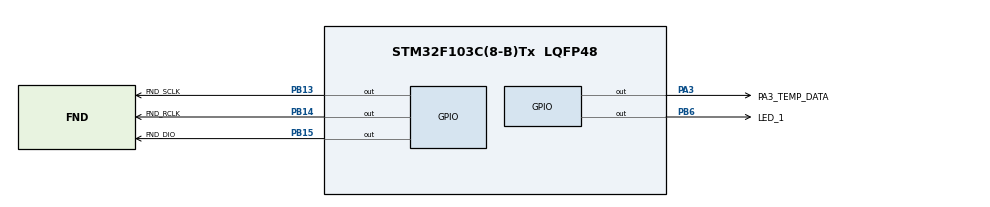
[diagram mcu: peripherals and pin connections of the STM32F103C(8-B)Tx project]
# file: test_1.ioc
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Mcu.Family=STM32F1
Mcu.Name=STM32F103C(8-B)Tx
Mcu.Package=LQFP48
NVIC.PriorityGroup=NVIC_PRIORITYGROUP_4
NVIC.TIM2_IRQn=true\:0\:0\:false\:false\:true\:true\:true\:true
PA3.GPIO_Label=PA3_TEMP_DATA
PA3.GPIO_ModeDefaultOutputPP=GPIO_MODE_OUTPUT_PP
PA3.GPIO_PuPd=GPIO_PULLUP
PA3.GPIO_Speed=GPIO_SPEED_FREQ_HIGH
PA3.PinState=GPIO_PIN_SET
PA3.Signal=GPIO_Output
PB13.GPIO_Label=FND_SCLK
PB13.GPIO_PuPd=GPIO_PULLUP
PB13.GPIO_Speed=GPIO_SPEED_FREQ_HIGH
PB13.PinState=GPIO_PIN_SET
PB13.Signal=GPIO_Output
PB14.GPIO_Label=FND_RCLK
PB14.GPIO_PuPd=GPIO_PULLUP
PB14.PinState=GPIO_PIN_SET
PB14.Signal=GPIO_Output
PB15.GPIO_Label=FND_DIO
PB15.GPIO_PuPd=GPIO_PULLDOWN
PB15.GPIO_Speed=GPIO_SPEED_FREQ_HIGH
PB15.PinState=GPIO_PIN_SET
PB15.Signal=GPIO_Output
PB6.GPIO_Label=LED_1
PB6.GPIO_ModeDefaultOutputPP=GPIO_MODE_OUTPUT_PP
PB6.GPIO_PuPd=GPIO_PULLUP
PB6.GPIO_Speed=GPIO_SPEED_FREQ_LOW
PB6.PinState=GPIO_PIN_SET
PB6.Signal=GPIO_Output
ProjectManager.HeapSize=0x200
ProjectManager.StackSize=0x400
ProjectManager.TargetToolchain=STM32CubeIDE
RCC.APB1Freq_Value=8000000
RCC.APB2Freq_Value=8000000
TIM2.Prescaler=(10000-1)
VP_SYS_VS_ND.Mode=No_Debug
VP_TIM2_VS_ClockSourceINT.Mode=Internal
board=custom

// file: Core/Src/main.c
/* USER CODE BEGIN Header */
/**
  ******************************************************************************
  * @file           : main.c
  * @brief          : Main program body
  ******************************************************************************
  * @attention
  *
  * Copyright (c) 2025 STMicroelectronics.
  * All rights reserved.
  *
  * This software is licensed under terms that can be found in the LICENSE file
  * in the root directory of this software component.
  * If no LICENSE file comes with this software, it is provided AS-IS.
  *
  ******************************************************************************
  */
/* USER CODE END Header */
#include "main.h"

/* USER CODE BEGIN Includes */
#include "fnd_controller.h"
/* USER CODE END Includes */

TIM_HandleTypeDef htim2;

void SystemClock_Config(void);
static void MX_GPIO_Init(void);
static void MX_TIM2_Init(void);

int main(void)
{

  /* USER CODE BEGIN 1 */
	Set_Up();

  /* USER CODE END 1 */

  /* MCU Configuration--------------------------------------------------------*/

  /* Reset of all peripherals, Initializes the Flash interface and the Systick. */
  HAL_Init();

  /* Configure the system clock */
  SystemClock_Config();

  /* Initialize all configured peripherals */
  MX_GPIO_Init();
  MX_TIM2_Init();
  /* USER CODE BEGIN 2 */
  HAL_TIM_Base_Start_IT(&htim2);
  /* USER CODE END 2 */

  /* Infinite loop */
  /* USER CODE BEGIN WHILE */
  while (1)
  {
	/* each segment's number
	  unsigned char a = 0b0001;
	for(int i = 0; i <= 8;i++)
	{
		send(~a);
		send(0b0001);
		HAL_GPIO_WritePin(FND_RCLK_GPIO_Port, FND_RCLK_Pin, 0);
		HAL_GPIO_WritePin(FND_RCLK_GPIO_Port, FND_RCLK_Pin, 1);
		a = a << 1;
		HAL_Delay(2000);
	}
	*/

	for (int i = 10; i <= 9999; i++) {
		digit_temper_replay(i, 50); //send counter 0-9999 with delay 50 cicles and hide zero
	}

    /* USER CODE END WHILE */

  }
}

void SystemClock_Config(void)
{
  RCC_OscInitTypeDef RCC_OscInitStruct = {0};
  RCC_ClkInitTypeDef RCC_ClkInitStruct = {0};

  /** Initializes the RCC Oscillators according to the specified parameters
  * in the RCC_OscInitTypeDef structure.
  */
  RCC_OscInitStruct.OscillatorType = RCC_OSCILLATORTYPE_HSI;
  RCC_OscInitStruct.HSIState = RCC_HSI_ON;
  RCC_OscInitStruct.HSICalibrationValue = RCC_HSICALIBRATION_DEFAULT;
  RCC_OscInitStruct.PLL.PLLState = RCC_PLL_NONE;
  if (HAL_RCC_OscConfig(&RCC_OscInitStruct) != HAL_OK)
  {
    Error_Handler();
  }

  /** Initializes the CPU, AHB and APB buses clocks
  */
  RCC_ClkInitStruct.ClockType = RCC_CLOCKTYPE_HCLK|RCC_CLOCKTYPE_SYSCLK
                              |RCC_CLOCKTYPE_PCLK1|RCC_CLOCKTYPE_PCLK2;
  RCC_ClkInitStruct.SYSCLKSource = RCC_SYSCLKSOURCE_HSI;
  RCC_ClkInitStruct.AHBCLKDivider = RCC_SYSCLK_DIV1;
  RCC_ClkInitStruct.APB1CLKDivider = RCC_HCLK_DIV1;
  RCC_ClkInitStruct.APB2CLKDivider = RCC_HCLK_DIV1;

  if (HAL_RCC_ClockConfig(&RCC_ClkInitStruct, FLASH_LATENCY_0) != HAL_OK)
  {
    Error_Handler();
  }
}

static void MX_TIM2_Init(void)
{

  TIM_ClockConfigTypeDef sClockSourceConfig = {0};
  TIM_MasterConfigTypeDef sMasterConfig = {0};

  htim2.Instance = TIM2;
  htim2.Init.Prescaler = (10000-1);
  htim2.Init.CounterMode = TIM_COUNTERMODE_UP;
  htim2.Init.Period = 65535;
  htim2.Init.ClockDivision = TIM_CLOCKDIVISION_DIV1;
  htim2.Init.AutoReloadPreload = TIM_AUTORELOAD_PRELOAD_DISABLE;
  if (HAL_TIM_Base_Init(&htim2) != HAL_OK)
  {
    Error_Handler();
  }
  sClockSourceConfig.ClockSource = TIM_CLOCKSOURCE_INTERNAL;
  if (HAL_TIM_ConfigClockSource(&htim2, &sClockSourceConfig) != HAL_OK)
  {
    Error_Handler();
  }
  sMasterConfig.MasterOutputTrigger = TIM_TRGO_RESET;
  sMasterConfig.MasterSlaveMode = TIM_MASTERSLAVEMODE_DISABLE;
  if (HAL_TIMEx_MasterConfigSynchronization(&htim2, &sMasterConfig) != HAL_OK)
  {
    Error_Handler();
  }

}

static void MX_GPIO_Init(void)
{
  GPIO_InitTypeDef GPIO_InitStruct = {0};

  /* GPIO Ports Clock Enable */
  __HAL_RCC_GPIOA_CLK_ENABLE();
  __HAL_RCC_GPIOB_CLK_ENABLE();

  /*Configure GPIO pin Output Level */
  HAL_GPIO_WritePin(PA3_TEMP_DATA_GPIO_Port, PA3_TEMP_DATA_Pin, GPIO_PIN_SET);

  /*Configure GPIO pin Output Level */
  HAL_GPIO_WritePin(GPIOB, FND_SCLK_Pin|FND_RCLK_Pin|FND_DIO_Pin|LED_1_Pin, GPIO_PIN_SET);

  /*Configure GPIO pin : PA3_TEMP_DATA_Pin */
  GPIO_InitStruct.Pin = PA3_TEMP_DATA_Pin;
  GPIO_InitStruct.Mode = GPIO_MODE_OUTPUT_PP;
  GPIO_InitStruct.Pull = GPIO_PULLUP;
  GPIO_InitStruct.Speed = GPIO_SPEED_FREQ_HIGH;
  HAL_GPIO_Init(PA3_TEMP_DATA_GPIO_Port, &GPIO_InitStruct);

  /*Configure GPIO pin : switch_1_Pin */
  GPIO_InitStruct.Pin = switch_1_Pin;
  GPIO_InitStruct.Mode = GPIO_MODE_INPUT;
  GPIO_InitStruct.Pull = GPIO_PULLUP;
  HAL_GPIO_Init(switch_1_GPIO_Port, &GPIO_InitStruct);

  /*Configure GPIO pin : FND_SCLK_Pin */
  GPIO_InitStruct.Pin = FND_SCLK_Pin;
  GPIO_InitStruct.Mode = GPIO_MODE_OUTPUT_PP;
  GPIO_InitStruct.Pull = GPIO_PULLUP;
  GPIO_InitStruct.Speed = GPIO_SPEED_FREQ_HIGH;
  HAL_GPIO_Init(FND_SCLK_GPIO_Port, &GPIO_InitStruct);

  /*Configure GPIO pins : FND_RCLK_Pin LED_1_Pin */
  GPIO_InitStruct.Pin = FND_RCLK_Pin|LED_1_Pin;
  GPIO_InitStruct.Mode = GPIO_MODE_OUTPUT_PP;
  GPIO_InitStruct.Pull = GPIO_PULLUP;
  GPIO_InitStruct.Speed = GPIO_SPEED_FREQ_LOW;
  HAL_GPIO_Init(GPIOB, &GPIO_InitStruct);

  /*Configure GPIO pin : FND_DIO_Pin */
  GPIO_InitStruct.Pin = FND_DIO_Pin;
  GPIO_InitStruct.Mode = GPIO_MODE_OUTPUT_PP;
  GPIO_InitStruct.Pull = GPIO_PULLDOWN;
  GPIO_InitStruct.Speed = GPIO_SPEED_FREQ_HIGH;
  HAL_GPIO_Init(FND_DIO_GPIO_Port, &GPIO_InitStruct);

}

void Error_Handler(void)
{
  __disable_irq();
  while (1)
  {
  }
}
